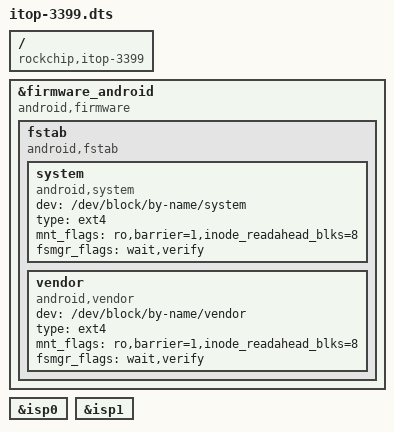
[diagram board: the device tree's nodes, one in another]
/*
 * Copyright (c) 2018 Fuzhou Rockchip Electronics Co., Ltd
 *
 * SPDX-License-Identifier: (GPL-2.0+ OR MIT)
 */

/dts-v1/;
#include "itop-3399.dtsi"

/ {
	compatible = "rockchip,itop-3399", "rockchip,rk3399";

};

&firmware_android {
	compatible = "android,firmware";
	fstab {
		compatible = "android,fstab";
		system {
			compatible = "android,system";
			dev = "/dev/block/by-name/system";
			type = "ext4";
			mnt_flags = "ro,barrier=1,inode_readahead_blks=8";
			fsmgr_flags = "wait,verify";
		};
		vendor {
			compatible = "android,vendor";
			dev = "/dev/block/by-name/vendor";
			type = "ext4";
			mnt_flags = "ro,barrier=1,inode_readahead_blks=8";
			fsmgr_flags = "wait,verify";
		};
	};
};

&isp0 {
	status = "okay";
};

&isp1 {
	status = "okay";
};
